# ESP32-S2 register map
Vendor: ESPRESSIF SYSTEMS (SHANGHAI) CO., LTD.; Series: ESP32 S-Series; File version: 20
CPU: Xtensa LX7 r0p0, little endian, no MPU, no FPU, 0 interrupt priority bits
Address unit: 32 bits
Registers are 32-bit, read-write, reset 0x0 unless marked. A register's access mark holds for its fields unless they carry their own. Offsets are from the block's base; [hi:lo] are bit positions; {n}, {i} and the like mark numbered series.

## PMS — Permissions Controller
Base 0x3F4C1000
0x00 SDIO_0 — SDIO permission control register 0.
  [0] SDIO_LOCK — Lock register. Setting to 1 locks SDIO permission control registers.
0x04 SDIO_1 — SDIO permission control register 1.
  [0] SDIO_DISABLE — Setting to 1 disables the SDIO function.
0x08 MAC_DUMP_0 — MAC dump permission control register 0.
  [0] MAC_DUMP_LOCK — Lock register. Setting to 1 locks MAC dump permission control registers.
0x0C MAC_DUMP_1 reset 0xE4 — MAC dump permission control register 1.
  [11:0] MAC_DUMP_CONNECT — Configure MAC dump connection.
0x10 PRO_IRAM0_0 — IBUS permission control register 0.
  [0] PRO_IRAM0_LOCK — Lock register. Setting to 1 locks IBUS permission control registers.
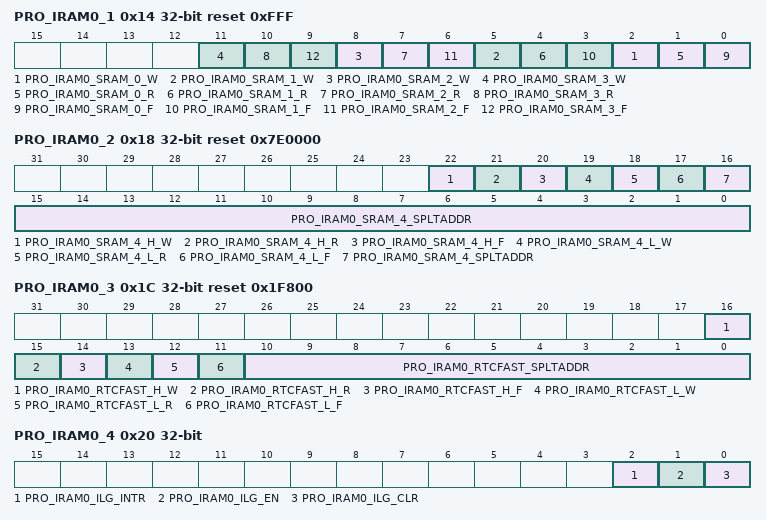
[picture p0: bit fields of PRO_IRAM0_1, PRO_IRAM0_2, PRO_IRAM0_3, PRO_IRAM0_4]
0x14 PRO_IRAM0_1 reset 0xFFF — IBUS permission control register 1.
  [3n+2] PRO_IRAM0_SRAM_{n}_W (n=0..3) — Setting to 1 grants IBUS permission to write SRAM Block {n}.
  [3n+1] PRO_IRAM0_SRAM_{n}_R (n=0..3) — Setting to 1 grants IBUS permission to read SRAM Block {n}.
  [3n] PRO_IRAM0_SRAM_{n}_F (n=0..3) — Setting to 1 grants IBUS permission to fetch SRAM Block {n}.
0x18 PRO_IRAM0_2 reset 0x7E0000 — IBUS permission control register 2.
  [22] PRO_IRAM0_SRAM_4_H_W — Setting to 1 grants IBUS permission to write SRAM Block 4-21 high address region.
  [21] PRO_IRAM0_SRAM_4_H_R — Setting to 1 grants IBUS permission to read SRAM Block 4-21 high address region.
  [20] PRO_IRAM0_SRAM_4_H_F — Setting to 1 grants IBUS permission to fetch SRAM Block 4-21 high address region.
  [19] PRO_IRAM0_SRAM_4_L_W — Setting to 1 grants IBUS permission to write SRAM Block 4-21 low address region.
  [18] PRO_IRAM0_SRAM_4_L_R — Setting to 1 grants IBUS permission to read SRAM Block 4-21 low address region.
  [17] PRO_IRAM0_SRAM_4_L_F — Setting to 1 grants IBUS permission to fetch SRAM Block 4-21 low address region.
  [16:0] PRO_IRAM0_SRAM_4_SPLTADDR — Configure the split address of SRAM Block 4-21 for IBUS access.
0x1C PRO_IRAM0_3 reset 0x1F800 — IBUS permission control register 3.
  [16] PRO_IRAM0_RTCFAST_H_W — Setting to 1 grants IBUS permission to write RTC FAST high address region.
  [15] PRO_IRAM0_RTCFAST_H_R — Setting to 1 grants IBUS permission to read RTC FAST high address region.
  [14] PRO_IRAM0_RTCFAST_H_F — Setting to 1 grants IBUS permission to fetch RTC FAST high address region.
  [13] PRO_IRAM0_RTCFAST_L_W — Setting to 1 grants IBUS permission to write RTC FAST low address region.
  [12] PRO_IRAM0_RTCFAST_L_R — Setting to 1 grants IBUS permission to read RTC FAST low address region.
  [11] PRO_IRAM0_RTCFAST_L_F — Setting to 1 grants IBUS permission to fetch RTC FAST low address region.
  [10:0] PRO_IRAM0_RTCFAST_SPLTADDR — Configure the split address of RTC FAST for IBUS access.
0x20 PRO_IRAM0_4 access per field — IBUS permission control register 4.
  [2] PRO_IRAM0_ILG_INTR ro — IBUS access interrupt signal.
  [1] PRO_IRAM0_ILG_EN rw — The enable signal for IBUS access interrupt.
  [0] PRO_IRAM0_ILG_CLR rw — The clear signal for IBUS access interrupt.
0x24 PRO_IRAM0_5 ro — IBUS status register.
  [21:0] PRO_IRAM0_ILG_ST — Record the illegitimate information of IBUS. [21:2]: store the bits [21:2] of IBUS address. [1]: 1 means data access, 0 means instruction access. [0]: 1 means write operation, 0 means read operation.
0x28 PRO_DRAM0_0 — DBUS permission control register 0.
  [0] PRO_DRAM0_LOCK — Lock register. Setting to 1 locks DBUS0 permission control registers.
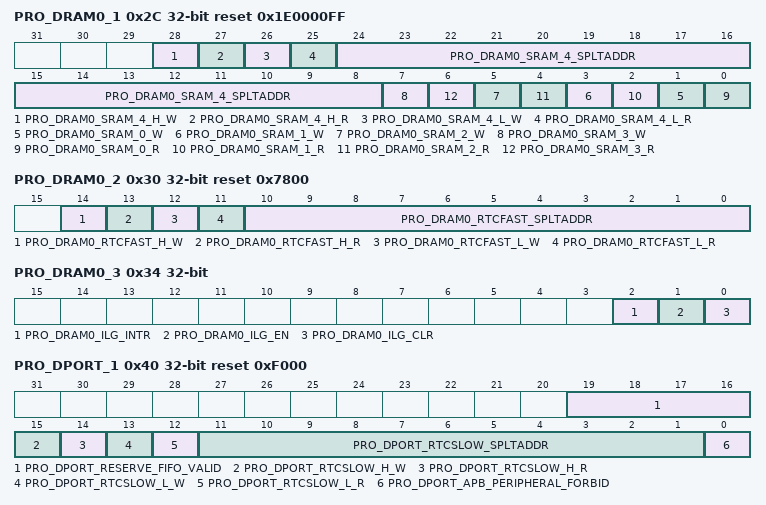
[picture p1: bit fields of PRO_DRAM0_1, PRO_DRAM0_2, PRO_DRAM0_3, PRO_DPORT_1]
0x2C PRO_DRAM0_1 reset 0x1E0000FF — DBUS permission control register 1.
  [28] PRO_DRAM0_SRAM_4_H_W — Setting to 1 grants DBUS0 permission to write SRAM Block 4-21 high address region.
  [27] PRO_DRAM0_SRAM_4_H_R — Setting to 1 grants DBUS0 permission to read SRAM Block 4-21 high address region.
  [26] PRO_DRAM0_SRAM_4_L_W — Setting to 1 grants DBUS0 permission to write SRAM Block 4-21 low address region.
  [25] PRO_DRAM0_SRAM_4_L_R — Setting to 1 grants DBUS0 permission to read SRAM Block 4-21 low address region.
  [24:8] PRO_DRAM0_SRAM_4_SPLTADDR — Configure the split address of SRAM Block 4-21 for DBUS0 access.
  [2n+1] PRO_DRAM0_SRAM_{n}_W (n=0..3) — Setting to 1 grants DBUS0 permission to write SRAM Block {n}.
  [2n] PRO_DRAM0_SRAM_{n}_R (n=0..3) — Setting to 1 grants DBUS0 permission to read SRAM Block {n}.
0x30 PRO_DRAM0_2 reset 0x7800 — DBUS permission control register 2.
  [14] PRO_DRAM0_RTCFAST_H_W — Setting to 1 grants DBUS0 permission to write RTC FAST high address region.
  [13] PRO_DRAM0_RTCFAST_H_R — Setting to 1 grants DBUS0 permission to read RTC FAST high address region.
  [12] PRO_DRAM0_RTCFAST_L_W — Setting to 1 grants DBUS0 permission to write RTC FAST low address region.
  [11] PRO_DRAM0_RTCFAST_L_R — Setting to 1 grants DBUS0 permission to read RTC FAST low address region.
  [10:0] PRO_DRAM0_RTCFAST_SPLTADDR — Configure the split address of RTC FAST for DBUS0 access.
0x34 PRO_DRAM0_3 access per field — DBUS permission control register 3.
  [2] PRO_DRAM0_ILG_INTR ro — DBUS0 access interrupt signal.
  [1] PRO_DRAM0_ILG_EN rw — The enable signal for DBUS0 access interrupt.
  [0] PRO_DRAM0_ILG_CLR rw — The clear signal for DBUS0 access interrupt.
0x38 PRO_DRAM0_4 ro — DBUS status register.
  [25:0] PRO_DRAM0_ILG_ST — Record the illegitimate information of DBUS. [25:6]: store the bits [21:2] of DBUS address. [5]: 1 means atomic access, 0 means nonatomic access. [4]: 1 means write operation, 0 means read operation. [3:0]: DBUS0 bus byte enables.
0x3C PRO_DPORT_0 — PeriBus1 permission control register 0.
  [0] PRO_DPORT_LOCK — Lock register. Setting to 1 locks PeriBus1 permission control registers.
0x40 PRO_DPORT_1 reset 0xF000 — PeriBus1 permission control register 1.
  [19:16] PRO_DPORT_RESERVE_FIFO_VALID — Configure whether to enable read protection for user-configured FIFO address.
  [15] PRO_DPORT_RTCSLOW_H_W — Setting to 1 grants PeriBus1 permission to write RTC FAST high address region.
  [14] PRO_DPORT_RTCSLOW_H_R — Setting to 1 grants PeriBus1 permission to read RTC FAST high address region.
  [13] PRO_DPORT_RTCSLOW_L_W — Setting to 1 grants PeriBus1 permission to write RTC FAST low address region.
  [12] PRO_DPORT_RTCSLOW_L_R — Setting to 1 grants PeriBus1 permission to read RTC FAST low address region.
  [11:1] PRO_DPORT_RTCSLOW_SPLTADDR — Configure the split address of RTC FAST for PeriBus1 access.
  [0] PRO_DPORT_APB_PERIPHERAL_FORBID — Setting to 1 denies PeriBus1 bus???s access to APB peripheral.
{0x3C+4i} PRO_DPORT_{i} (i=2..5) — PeriBus1 permission control register {i}.
  [17:0] PRO_DPORT_RESERVE_FIFO_{i-2} — Configure read-protection address {i-2}.
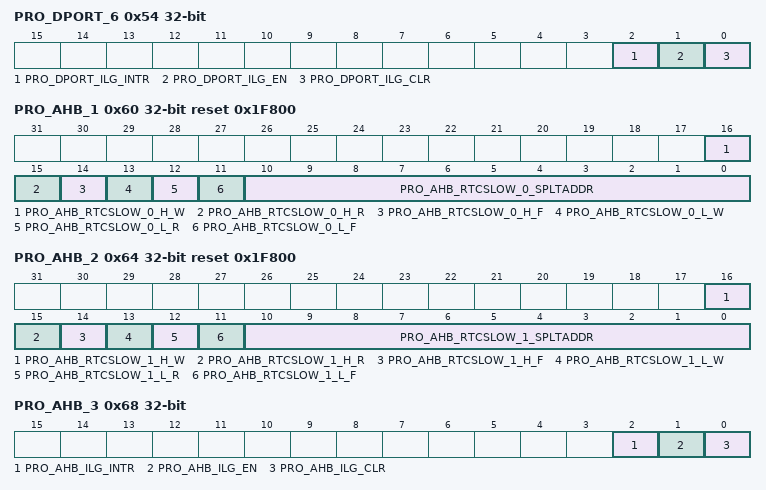
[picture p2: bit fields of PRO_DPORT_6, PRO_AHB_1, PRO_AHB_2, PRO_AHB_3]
0x54 PRO_DPORT_6 access per field — PeriBus1 permission control register 6.
  [2] PRO_DPORT_ILG_INTR ro — PeriBus1 access interrupt signal.
  [1] PRO_DPORT_ILG_EN rw — The enable signal for PeriBus1 access interrupt.
  [0] PRO_DPORT_ILG_CLR rw — The clear signal for PeriBus1 access interrupt.
0x58 PRO_DPORT_7 ro — PeriBus1 status register.
  [25:0] PRO_DPORT_ILG_ST — Record the illegitimate information of PeriBus1. [25:6]: store the bits [21:2] of PeriBus1 address. [5]: 1 means atomic access, 0 means nonatomic access. [4]: if bits [31:22] of PeriBus1 address are 0xfd, then the bit value is 1, otherwise it is 0. [3:0]: PeriBus1 byte enables.
0x5C PRO_AHB_0 — PeriBus2 permission control register 0.
  [0] PRO_AHB_LOCK — Lock register. Setting to 1 locks PeriBus2 permission control registers.
0x60 PRO_AHB_1 reset 0x1F800 — PeriBus2 permission control register 1.
  [16] PRO_AHB_RTCSLOW_0_H_W — Setting to 1 grants PeriBus2 permission to write RTCSlow_0 high address region.
  [15] PRO_AHB_RTCSLOW_0_H_R — Setting to 1 grants PeriBus2 permission to read RTCSlow_0 high address region.
  [14] PRO_AHB_RTCSLOW_0_H_F — Setting to 1 grants PeriBus2 permission to fetch RTCSlow_0 high address region.
  [13] PRO_AHB_RTCSLOW_0_L_W — Setting to 1 grants PeriBus2 permission to write RTCSlow_0 low address region.
  [12] PRO_AHB_RTCSLOW_0_L_R — Setting to 1 grants PeriBus2 permission to read RTCSlow_0 low address region.
  [11] PRO_AHB_RTCSLOW_0_L_F — Setting to 1 grants PeriBus2 permission to fetch RTCSlow_0 low address region.
  [10:0] PRO_AHB_RTCSLOW_0_SPLTADDR — Configure the split address of RTCSlow_0 for PeriBus2 access.
0x64 PRO_AHB_2 reset 0x1F800 — PeriBus2 permission control register 2.
  [16] PRO_AHB_RTCSLOW_1_H_W — Setting to 1 grants PeriBus2 permission to write RTCSlow_1 high address region.
  [15] PRO_AHB_RTCSLOW_1_H_R — Setting to 1 grants PeriBus2 permission to read RTCSlow_1 high address region.
  [14] PRO_AHB_RTCSLOW_1_H_F — Setting to 1 grants PeriBus2 permission to fetch RTCSlow_1 high address region.
  [13] PRO_AHB_RTCSLOW_1_L_W — Setting to 1 grants PeriBus2 permission to write RTCSlow_1 low address region.
  [12] PRO_AHB_RTCSLOW_1_L_R — Setting to 1 grants PeriBus2 permission to read RTCSlow_1 low address region.
  [11] PRO_AHB_RTCSLOW_1_L_F — Setting to 1 grants PeriBus2 permission to fetch RTCSlow_1 low address region.
  [10:0] PRO_AHB_RTCSLOW_1_SPLTADDR — Configure the split address of RTCSlow_1 for PeriBus2 access.
0x68 PRO_AHB_3 access per field — PeriBus2 permission control register 3.
  [2] PRO_AHB_ILG_INTR ro — PeriBus2 access interrupt signal.
  [1] PRO_AHB_ILG_EN rw — The enable signal for PeriBus2 access interrupt.
  [0] PRO_AHB_ILG_CLR rw — The clear signal for PeriBus2 access interrupt.
0x6C PRO_AHB_4 ro — PeriBus2 status register.
  [31:0] PRO_AHB_ILG_ST — Record the illegitimate information of PeriBus2. [31:2]: store the bits [31:2] of PeriBus2 address. [1]: 1 means data access, 0 means instruction access. [0]: 1 means write operation, 0 means read operation.
0x70 PRO_TRACE_0 — Trace memory permission control register 0.
  [0] PRO_TRACE_LOCK — Lock register. Setting to 1 locks trace function permission control registers.
0x74 PRO_TRACE_1 — Trace memory permission control register 1.
  [0] PRO_TRACE_DISABLE — Setting to 1 disables the trace memory function.
0x78 PRO_CACHE_0 — Cache permission control register 0.
  [0] PRO_CACHE_LOCK — Lock register. Setting to 1 locks cache permission control registers.
0x7C PRO_CACHE_1 — Cache permission control register 1.
  [15:0] PRO_CACHE_CONNECT — Configure which SRAM Block will be occupied by Icache or Dcache.
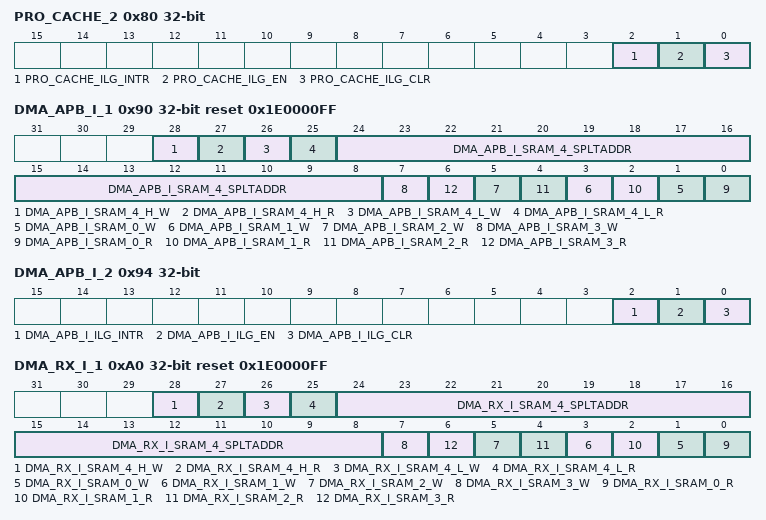
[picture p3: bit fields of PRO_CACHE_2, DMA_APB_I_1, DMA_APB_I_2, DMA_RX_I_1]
0x80 PRO_CACHE_2 access per field — Cache permission control register 2.
  [2] PRO_CACHE_ILG_INTR ro — Cache access interrupt signal.
  [1] PRO_CACHE_ILG_EN rw — The enable signal for cache access interrupt.
  [0] PRO_CACHE_ILG_CLR rw — The clear signal for cache access interrupt.
0x84 PRO_CACHE_3 ro — Icache status register.
  [16:0] PRO_CACHE_ILG_ST_I — Record the illegitimate information of ICache to access memory. [16]: access enable, active low. [15:4]: store the bits [11:0] of address. [3:0]: Icache bus write byte enables, active low.
0x88 PRO_CACHE_4 ro — Dcache status register.
  [16:0] PRO_CACHE_ILG_ST_D — Record the illegitimate information of Dcache to access memory. [16]: access enable, active low. [15:4]: store the bits [11:0] of address. [3:0]: Dcache bus write byte enables, active low.
0x8C DMA_APB_I_0 — Internal DMA permission control register 0.
  [0] DMA_APB_I_LOCK — Lock register. Setting to 1 locks internal DMA permission control registers.
0x90 DMA_APB_I_1 reset 0x1E0000FF — Internal DMA permission control register 1.
  [28] DMA_APB_I_SRAM_4_H_W — Setting to 1 grants internal DMA permission to write SRAM Block 4-21 high address region.
  [27] DMA_APB_I_SRAM_4_H_R — Setting to 1 grants internal DMA permission to read SRAM Block 4-21 high address region.
  [26] DMA_APB_I_SRAM_4_L_W — Setting to 1 grants internal DMA permission to write SRAM Block 4-21 low address region.
  [25] DMA_APB_I_SRAM_4_L_R — Setting to 1 grants internal DMA permission to read SRAM Block 4-21 low address region.
  [24:8] DMA_APB_I_SRAM_4_SPLTADDR — Configure the split address of SRAM Block 4-21 for internal DMA access.
  [2n+1] DMA_APB_I_SRAM_{n}_W (n=0..3) — Setting to 1 grants internal DMA permission to write SRAM Block {n}.
  [2n] DMA_APB_I_SRAM_{n}_R (n=0..3) — Setting to 1 grants internal DMA permission to read SRAM Block {n}.
0x94 DMA_APB_I_2 access per field — Internal DMA permission control register 2.
  [2] DMA_APB_I_ILG_INTR ro — Internal DMA access interrupt signal.
  [1] DMA_APB_I_ILG_EN rw — The enable signal for internal DMA access interrupt.
  [0] DMA_APB_I_ILG_CLR rw — The clear signal for internal DMA access interrupt.
0x98 DMA_APB_I_3 ro — Internal DMA status register.
  [22:0] DMA_APB_I_ILG_ST — Record the illegitimate information of Internal DMA. [22:6]: store the bits [18:2] of address. [5]: if bits [31:19] of address are 0x7ff, then the bit value is 1, otherwise it is 0. [4]: 1 means write operation, 0 means read operation. [3:0]: Internal DMA bus byte enables.
0x9C DMA_RX_I_0 — RX Copy DMA permission control register 0.
  [0] DMA_RX_I_LOCK — Lock register. Setting to 1 locks RX Copy DMA permission control registers.
0xA0 DMA_RX_I_1 reset 0x1E0000FF — RX Copy DMA permission control register 1.
  [28] DMA_RX_I_SRAM_4_H_W — Setting to 1 grants RX Copy DMA permission to write SRAM Block 4~21 high address region.
  [27] DMA_RX_I_SRAM_4_H_R — Setting to 1 grants RX Copy DMA permission to read SRAM Block 4-21 high address region.
  [26] DMA_RX_I_SRAM_4_L_W — Setting to 1 grants RX Copy DMA permission to write SRAM Block 4-21 low address region.
  [25] DMA_RX_I_SRAM_4_L_R — Setting to 1 grants RX Copy DMA permission to read SRAM Block 4-21 low address region.
  [24:8] DMA_RX_I_SRAM_4_SPLTADDR — Configure the split address of SRAM Block 4-21 for RX Copy DMA access.
  [2n+1] DMA_RX_I_SRAM_{n}_W (n=0..3) — Setting to 1 grants RX Copy DMA permission to write SRAM Block {n}.
  [2n] DMA_RX_I_SRAM_{n}_R (n=0..3) — Setting to 1 grants RX Copy DMA permission to read SRAM Block {n}.
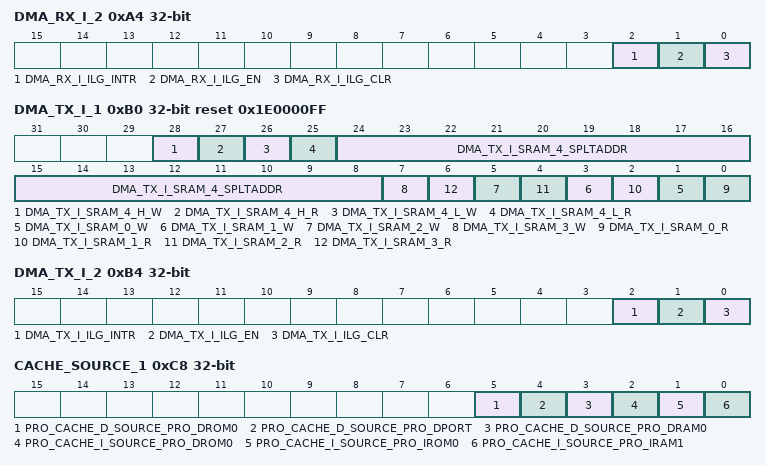
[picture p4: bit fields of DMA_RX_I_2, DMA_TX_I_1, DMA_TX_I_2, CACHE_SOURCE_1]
0xA4 DMA_RX_I_2 access per field — RX Copy DMA permission control register 2.
  [2] DMA_RX_I_ILG_INTR ro — RX Copy DMA access interrupt signal.
  [1] DMA_RX_I_ILG_EN rw — The enable signal for RX Copy DMA access interrupt.
  [0] DMA_RX_I_ILG_CLR rw — The clear signal for RX Copy DMA access interrupt.
0xA8 DMA_RX_I_3 ro — RX Copy DMA status register.
  [22:0] DMA_RX_I_ILG_ST — Record the illegitimate information of RX Copy DMA. [22:6]: store the bits [18:2] of address. [5]: if bits [31:19] of address are 0x7ff, then the bit value is 1, otherwise it is 0. [4]: 1 means write operation, 0 means read operation. [3:0]: RX Copy DMA bus byte enables.
0xAC DMA_TX_I_0 — TX Copy DMA permission control register 0.
  [0] DMA_TX_I_LOCK — Lock register. Setting to 1 locks TX Copy DMA permission control registers.
0xB0 DMA_TX_I_1 reset 0x1E0000FF — TX Copy DMA permission control register 1.
  [28] DMA_TX_I_SRAM_4_H_W — Setting to 1 grants TX Copy DMA permission to write SRAM Block 4-21 high address region.
  [27] DMA_TX_I_SRAM_4_H_R — Setting to 1 grants TX Copy DMA permission to read SRAM Block 4-21 high address region.
  [26] DMA_TX_I_SRAM_4_L_W — Setting to 1 grants TX Copy DMA permission to write SRAM Block 4-21 low address region.
  [25] DMA_TX_I_SRAM_4_L_R — Setting to 1 grants TX Copy DMA permission to read SRAM Block 4-21 low address region.
  [24:8] DMA_TX_I_SRAM_4_SPLTADDR — Configure the split address of SRAM Block 4-21 for TX Copy DMA access.
  [2n+1] DMA_TX_I_SRAM_{n}_W (n=0..3) — Setting to 1 grants TX Copy DMA permission to write SRAM Block {n}.
  [2n] DMA_TX_I_SRAM_{n}_R (n=0..3) — Setting to 1 grants TX Copy DMA permission to read SRAM Block {n}.
0xB4 DMA_TX_I_2 access per field — TX Copy DMA permission control register 2.
  [2] DMA_TX_I_ILG_INTR ro — TX Copy DMA access interrupt signal.
  [1] DMA_TX_I_ILG_EN rw — The enable signal for TX Copy DMA access interrupt.
  [0] DMA_TX_I_ILG_CLR rw — The clear signal for TX Copy DMA access interrupt.
0xB8 DMA_TX_I_3 ro — TX Copy DMA status register.
  [22:0] DMA_TX_I_ILG_ST — Record the illegitimate information of TX Copy DMA. [22:6]: store the bits [18:2] of address. [5]: if bits [31:19] of address are 0x7ff, then the bit value is 1, otherwise it is 0. [4]: 1 means write operation, 0 means read operation. [3:0]: TX Copy DMA bus byte enables.
0xBC PRO_BOOT_LOCATION_0 — Boot permission control register 0.
  [0] PRO_BOOT_LOCATION_LOCK — Lock register. Setting to 1 locks boot remap permission control registers.
0xC0 PRO_BOOT_LOCATION_1 — Boot permission control register 1.
  [0] PRO_BOOT_REMAP — If set to 1, enable boot remap function.
0xC4 CACHE_SOURCE_0 — Cache access permission control register 0.
  [0] CACHE_SOURCE_LOCK — Lock register. Setting to 1 locks cache access permission control registers.
0xC8 CACHE_SOURCE_1 — Cache access permission control register 1.
  [5] PRO_CACHE_D_SOURCE_PRO_DROM0 — xx
  [4] PRO_CACHE_D_SOURCE_PRO_DPORT — xx
  [3] PRO_CACHE_D_SOURCE_PRO_DRAM0 — xx
  [2] PRO_CACHE_I_SOURCE_PRO_DROM0 — xx
  [1] PRO_CACHE_I_SOURCE_PRO_IROM0 — xx
  [0] PRO_CACHE_I_SOURCE_PRO_IRAM1 — xx
0xCC APB_PERIPHERAL_0 — Peripheral access permission control register 0.
  [0] APB_PERIPHERAL_LOCK — Lock register. Setting to 1 locks TX Copy DMA permission control registers.
0xD0 APB_PERIPHERAL_1 reset 0x1 — Peripheral access permission control register 1.
  [0] APB_PERIPHERAL_SPLIT_BURST — Setting to 1 splits the data phase of the last access and the address phase of following access.
0xD4 OCCUPY_0 — Occupy permission control register 0.
  [0] OCCUPY_LOCK — Lock register. Setting to 1 locks occupy permission control registers.
0xD8 OCCUPY_1 — Occupy permission control register 1.
  [3:0] OCCUPY_CACHE — Configure whether SRAM Block 0-3 is used as cache memory.
0xDC OCCUPY_2 — Occupy permission control register 2.
  [3:0] OCCUPY_MAC_DUMP — Configure whether SRAM Block 18-21 is used as mac dump.
0xE0 OCCUPY_3 — Occupy permission control register 3.
  [17:0] OCCUPY_PRO_TRACE — Configure one block of SRAM Block 4-21 is used as trace memory.
0xE4 CACHE_TAG_ACCESS_0 — Cache tag permission control register 0.
  [0] CACHE_TAG_ACCESS_LOCK — Lock register. Setting to 1 locks cache tag permission control registers.
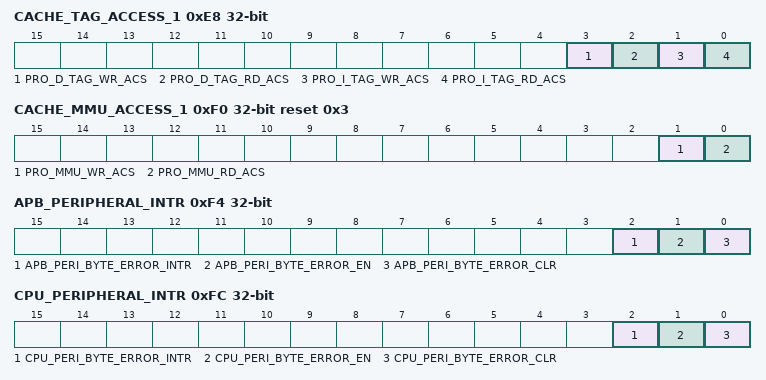
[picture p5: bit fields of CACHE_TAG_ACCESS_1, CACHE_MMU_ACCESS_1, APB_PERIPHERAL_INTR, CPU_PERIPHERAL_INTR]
0xE8 CACHE_TAG_ACCESS_1 — Cache tag permission control register 1.
  [3] PRO_D_TAG_WR_ACS — Setting to 1 permits write access to Dcache tag memory.
  [2] PRO_D_TAG_RD_ACS — Setting to 1 permits read access to Dcache tag memory.
  [1] PRO_I_TAG_WR_ACS — Setting to 1 permits write access to Icache tag memory.
  [0] PRO_I_TAG_RD_ACS — Setting to 1 permits read access to Icache tag memory.
0xEC CACHE_MMU_ACCESS_0 — Cache MMU permission control register 0.
  [0] CACHE_MMU_ACCESS_LOCK — Lock register. Setting to 1 locks cache MMU permission control registers.
0xF0 CACHE_MMU_ACCESS_1 reset 0x3 — Cache MMU permission control register 1.
  [1] PRO_MMU_WR_ACS — Setting to 1 permits write access to MMU memory.
  [0] PRO_MMU_RD_ACS — Setting to 1 permits read access to MMU memory.
0xF4 APB_PERIPHERAL_INTR access per field — PeribBus2 permission control register.
  [2] APB_PERI_BYTE_ERROR_INTR ro — APB peripheral access interrupt signal.
  [1] APB_PERI_BYTE_ERROR_EN rw — The enable signal for APB peripheral access interrupt.
  [0] APB_PERI_BYTE_ERROR_CLR rw — The clear signal for APB peripheral interrupt.
0xF8 APB_PERIPHERAL_STATUS ro — PeribBus2 peripheral access status register.
  [31:0] APB_PERI_BYTE_ERROR_ADDR — Record the illegitimate address of APB peripheral.
0xFC CPU_PERIPHERAL_INTR access per field — PeribBus1 permission control register.
  [2] CPU_PERI_BYTE_ERROR_INTR ro — CPU peripheral access interrupt signal.
  [1] CPU_PERI_BYTE_ERROR_EN rw — The enable signal for CPU peripheral access interrupt.
  [0] CPU_PERI_BYTE_ERROR_CLR rw — The clear signal for CPU peripheral access interrupt.
0x100 CPU_PERIPHERAL_STATUS ro — PeribBus1 peripheral access status register.
  [31:0] CPU_PERI_BYTE_ERROR_ADDR — Record the illegitimate address of CPU peripheral.
0x104 CLOCK_GATE reset 0x1 — Clock gate register of permission control.
  [0] CLK_EN — Enable the clock of permission control module when set to 1.
0xFFC DATE reset 0x1905090 — Version control register.
  [27:0] DATE
